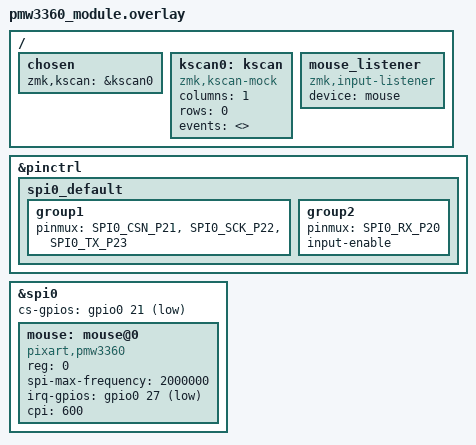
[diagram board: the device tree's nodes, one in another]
/*
 * Copyright (c) 2025 George Norton
 *
 * SPDX-License-Identifier: MIT
 */

#include <zephyr/dt-bindings/input/input-event-codes.h>
#include <dt-bindings/zmk/matrix_transform.h>
#include <physical_layouts.dtsi>

/ {
	chosen {
        zmk,kscan = &kscan0;
    };

	kscan0: kscan {
        compatible = "zmk,kscan-mock";
        columns = <1>;
        rows = <0>;

        events = <>;
	};
};


&pinctrl {
	spi0_default: spi0_default {
		group1 {
			pinmux = <SPI0_CSN_P21>, <SPI0_SCK_P22>, <SPI0_TX_P23>;
		};
		group2 {
			pinmux = <SPI0_RX_P20>;
			input-enable;
		};
	};
};


&spi0 {
	status = "okay";
	cs-gpios = <&gpio0 21 GPIO_ACTIVE_LOW>;
	mouse: mouse@0 {
		compatible = "pixart,pmw3360";
		status = "okay";
		reg = <0>;
		spi-max-frequency = <2000000>;

		// pmw3360 driver parameters
		irq-gpios = <&gpio0 27 (GPIO_ACTIVE_LOW | GPIO_PULL_UP)>;
		cpi = <600>;
	};
};

/ {
	mouse_listener {
		compatible = "zmk,input-listener";
		device = <&mouse>;
	};
};
